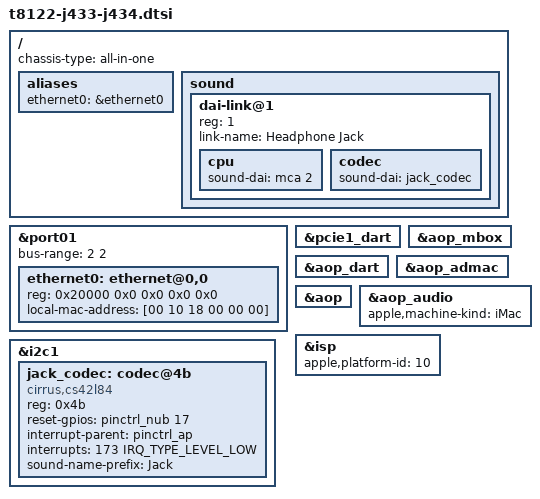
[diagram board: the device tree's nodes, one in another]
// SPDX-License-Identifier: GPL-2.0+ OR MIT
/*
 * Apple iMac (24-inch, M3, 2023)
 *
 * This file contains the parts common to J433 and J434 devices with t8122.
 *
 * target-type: J433, J434
 *
 * Copyright The Asahi Linux Contributors
 */

#include "t8122-usbpd-i2c.dtsi"
#include "t8122-jxxx.dtsi"

/ {
	chassis-type = "all-in-one";

	aliases {
		ethernet0 = &ethernet0;
	};
};

&port01 {
	bus-range = <2 2>;
	status = "okay";
	ethernet0: ethernet@0,0 {
		reg = <0x20000 0x0 0x0 0x0 0x0>;
		/* To be filled by the loader */
		local-mac-address = [00 10 18 00 00 00];
	};
};

&pcie1_dart {
	status = "okay";
};

/* The mics and the ambient light sensor, as on the M1 iMacs; untested here. */
&aop_mbox {
	status = "okay";
};

&aop_dart {
	status = "okay";
};

&aop_admac {
	status = "okay";
};

&aop {
	status = "okay";
};

&aop_audio {
	apple,machine-kind = "iMac";
};

&i2c1 {
	jack_codec: codec@4b {
		compatible = "cirrus,cs42l84";
		reg = <0x4b>;
		reset-gpios = <&pinctrl_nub 17 GPIO_ACTIVE_HIGH>;
		interrupt-parent = <&pinctrl_ap>;
		interrupts = <173 IRQ_TYPE_LEVEL_LOW>;
		#sound-dai-cells = <0>;
		sound-name-prefix = "Jack";
	};
};

/ {
	sound: sound {
		#address-cells = <1>;
		#size-cells = <0>;

		dai-link@1 {
			reg = <1>;
			link-name = "Headphone Jack";

			cpu {
				sound-dai = <&mca 2>;
			};
			codec {
				sound-dai = <&jack_codec>;
			};
		};
	};
};

#include "isp-imx364.dtsi"

&isp {
	apple,platform-id = <10>;
};

#include "hwmon-fan-dual.dtsi"
